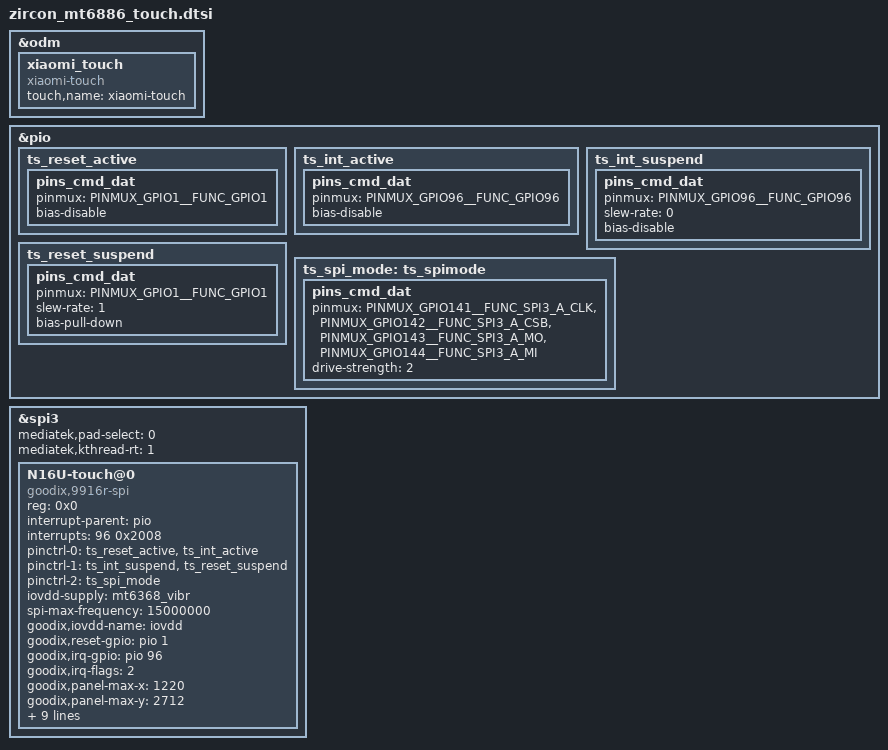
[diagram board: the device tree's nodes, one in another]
&odm {
	xiaomi_touch: xiaomi_touch {
		compatible = "xiaomi-touch";
		status = "ok";
		touch,name = "xiaomi-touch";
	};
};
&pio{
	ts_reset_active: ts_reset_active {
		pins_cmd_dat {
			pinmux = <PINMUX_GPIO1__FUNC_GPIO1>;
			bias-disable;
		};
	};
	ts_int_active: ts_int_active {
		pins_cmd_dat {
			pinmux = <PINMUX_GPIO96__FUNC_GPIO96>;
			bias-disable;
		};
	};
	ts_int_suspend: ts_int_suspend {
		pins_cmd_dat {
			pinmux = <PINMUX_GPIO96__FUNC_GPIO96>;
			slew-rate = <0>;
			bias-disable;
		};
	};
	ts_reset_suspend: ts_reset_suspend {
		pins_cmd_dat {
			pinmux = <PINMUX_GPIO1__FUNC_GPIO1>;
			slew-rate = <1>;
			bias-pull-down;
		};
	};
	ts_spi_mode: ts_spimode {
		pins_cmd_dat {
			pinmux = <PINMUX_GPIO141__FUNC_SPI3_A_CLK>,
				<PINMUX_GPIO142__FUNC_SPI3_A_CSB>,
				<PINMUX_GPIO143__FUNC_SPI3_A_MO>,
				<PINMUX_GPIO144__FUNC_SPI3_A_MI>;
			drive-strength = <2>;
		};
	};
	/*
	ts_dvdd_enable: ts_dvddenable {
		pins_cmd_dat {
			pinmux = <PINMUX_GPIO94__FUNC_GPIO94>;
			output-high;
		};
	};
	ts_dvdd_disable: ts_dvdddisable {
		pins_cmd_dat {
			pinmux = <PINMUX_GPIO94__FUNC_GPIO94>;
			output-low;
		};
	};
	*/

};
&spi3 {
	mediatek,pad-select = <0>;
	mediatek,kthread-rt = <1>;
	status = "ok";
	N16U-touch@0 {
		status = "ok";
		compatible = "goodix,9916r-spi";
		reg = <0x0>;
		interrupt-parent = <&pio>;
		interrupts = <96 0x2008>;
		pinctrl-names = "pmx_ts_active", "pmx_ts_suspend", "pmx_ts_spi_mode";
		pinctrl-0 = <&ts_reset_active &ts_int_active>;
		pinctrl-1 = <&ts_int_suspend &ts_reset_suspend>;
		pinctrl-2 = <&ts_spi_mode>;
		iovdd-supply = <&mt6368_vibr>;
		spi-max-frequency = <15000000>;

		goodix,iovdd-name = "iovdd";
		goodix,reset-gpio = <&pio 1 0x00>;
		goodix,irq-gpio = <&pio 96 0x2808>;
		goodix,irq-flags = <2>;
		goodix,panel-max-x = <1220>;
		goodix,panel-max-y = <2712>;
		goodix,panel-max-w = <255>;
		goodix,panel-max-p = <4096>;
		goodix,avdd-gpio = <&pio 132 0x00>; 
		goodix,firmware-name = "goodix_firmware_n16u_CSOT.bin";
		goodix,config-name = "goodix_cfg_group_n16u_CSOT.bin";
		goodix,touch-expert-array = <2 3 2 2
					     4 3 3 2
					     3 3 4 2>;
	};
};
